AUTOSAR XML (schema 4-2-2)
package /ComponentTypes
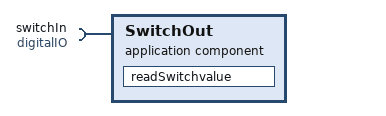
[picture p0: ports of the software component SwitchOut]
  application sw component type SwitchOut
    require port switchIn: nonqueued-receiver-com-spec{data-element=boolean, init-value=0}, required-interface=digitalIO
    behavior SwitchOut_InternalBehavior
      data received event DRT_switch_switchIn_boolean: start-on-event=readSwitchvalue, data=switchIn.boolean
      runnable readSwitchvalue
        data-receive-point-by-arguments:
          access REC_switchIn_boolean: accessed-variable=switchIn.boolean
  swc implementation SwitchOut_Implementation: behavior=SwitchOut_InternalBehavior
